# R7FA6M4AF register map
Vendor: Renesas Electronics Corporation; Series: RA6; File version: 1.20.04
CPU: CM33 r0p4, little endian, MPU, FPU, VTOR, 4 interrupt priority bits, 96 interrupts
Registers are 8-bit, read-write, reset 0x0 unless marked. A register's access mark holds for its fields unless they carry their own. Offsets are from the block's base; [hi:lo] are bit positions; {n}, {i} and the like mark numbered series; 'fields as' and 'values as' point back to an identical list; <NAME> marks a mode.

## GPT320 (part 2 of 2) — General PWM 32-bit Timer 0
Base 0x40169000
Same registers: GPT321 0x40169100, GPT322 0x40169200, GPT323 0x40169300
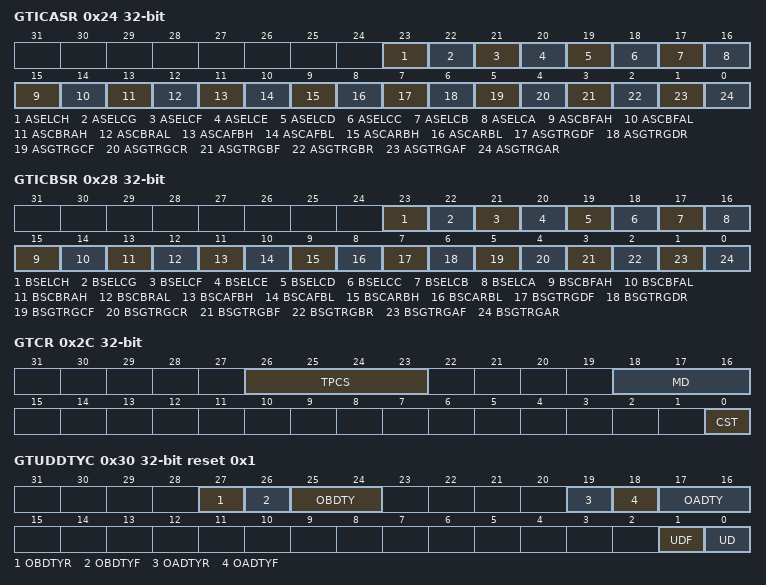
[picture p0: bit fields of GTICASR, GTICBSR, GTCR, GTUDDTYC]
0x24 GTICASR 32-bit — General PWM Timer Input Capture Source Select Register A
  [23] ASELCH — ELC_GPTH Event Source GTCCRA Input Capture Enable
    0=GTCCRA input capture disabled at the ELC_GPTH input; 1=GTCCRA input capture enabled at the ELC_GPTH input
  [22] ASELCG — ELC_GPTG Event Source GTCCRA Input Capture Enable
    0=GTCCRA input capture disabled at the ELC_GPTG input; 1=GTCCRA input capture enabled at the ELC_GPTG input
  [21] ASELCF — ELC_GPTF Event Source GTCCRA Input Capture Enable
    0=GTCCRA input capture disabled at the ELC_GPTF input; 1=GTCCRA input capture enabled at the ELC_GPTF input
  [20] ASELCE — ELC_GPTE Event Source GTCCRA Input Capture Enable
    0=GTCCRA input capture disabled at the ELC_GPTE input; 1=GTCCRA input capture enabled at the ELC_GPTE input
  [19] ASELCD — ELC_GPTD Event Source GTCCRA Input Capture Enable
    0=GTCCRA input capture disabled at the ELC_GPTD input; 1=GTCCRA input capture enabled at the ELC_GPTD input
  [18] ASELCC — ELC_GPTC Event Source GTCCRA Input Capture Enable
    0=GTCCRA input capture disabled at the ELC_GPTC input; 1=GTCCRA input capture enabled at the ELC_GPTC input
  [17] ASELCB — ELC_GPTB Event Source GTCCRA Input Capture Enable
    0=GTCCRA input capture disabled at the ELC_GPTB input; 1=GTCCRA input capture enabled at the ELC_GPTB input
  [16] ASELCA — ELC_GPTA Event Source GTCCRA Input Capture Enable
    0=GTCCRA input capture disabled at the ELC_GPTA input; 1=GTCCRA input capture enabled at the ELC_GPTA input
  [15] ASCBFAH — GTIOCnB Pin Falling Input during GTIOCnA Value High Source GTCCRA Input Capture Enable
    0=GTCCRA input capture disabled on the falling edge of GTIOCnB input when GTIOCnA input is 1; 1=GTCCRA input capture enabled on the falling edge of GTIOCnB input when GTIOCnA input is 1
  [14] ASCBFAL — GTIOCnB Pin Falling Input during GTIOCnA Value Low Source GTCCRA Input Capture Enable
    0=GTCCRA input capture disabled on the falling edge of GTIOCnB input when GTIOCnA input is 0; 1=GTCCRA input capture enabled on the falling edge of GTIOCnB input when GTIOCnA input is 0
  [13] ASCBRAH — GTIOCnB Pin Rising Input during GTIOCnA Value High Source GTCCRA Input Capture Enable
    0=GTCCRA input capture disabled on the rising edge of GTIOCnB input when GTIOCnA input is 1; 1=GTCCRA input capture enabled on the rising edge of GTIOCnB input when GTIOCnA input is 1
  [12] ASCBRAL — GTIOCnB Pin Rising Input during GTIOCnA Value Low Source GTCCRA Input Capture Enable
    0=GTCCRA input capture disabled on the rising edge of GTIOCnB input when GTIOCnA input is 0; 1=GTCCRA input capture enabled on the rising edge of GTIOCnB input when GTIOCnA input is 0
  [11] ASCAFBH — GTIOCnA Pin Falling Input during GTIOCnB Value High Source GTCCRA Input Capture Enable
    0=GTCCRA input capture disabled on the falling edge of GTIOCnA input when GTIOCnB input is 1; 1=GTCCRA input capture enabled on the falling edge of GTIOCnA input when GTIOCnB input is 1
  [10] ASCAFBL — GTIOCnA Pin Falling Input during GTIOCnB Value Low Source GTCCRA Input Capture Enable
    0=GTCCRA input capture disabled on the falling edge of GTIOCnA input when GTIOCnB input is 0; 1=GTCCRA input capture enabled on the falling edge of GTIOCnA input when GTIOCnB input is 0
  [9] ASCARBH — GTIOCnA Pin Rising Input during GTIOCnB Value High Source GTCCRA Input Capture Enable
    0=GTCCRA input capture disabled on the rising edge of GTIOCnA input when GTIOCnB input is 1; 1=GTCCRA input capture enabled on the rising edge of GTIOCnA input when GTIOCnB input is 1
  [8] ASCARBL — GTIOCnA Pin Rising Input during GTIOCnB Value Low Source GTCCRA Input Capture Enable
    0=GTCCRA input capture disabled on the rising edge of GTIOCnA input when GTIOCnB input is 0; 1=GTCCRA input capture enabled on the rising edge of GTIOCnA input when GTIOCnB input is 0
  [7] ASGTRGDF — GTETRGD Pin Falling Input Source GTCCRA Input Capture Enable
    0=GTCCRA input capture disabled on the falling edge of GTETRGD input; 1=GTCCRA input capture enabled on the falling edge of GTETRGD input
  [6] ASGTRGDR — GTETRGD Pin Rising Input Source GTCCRA Input Capture Enable
    0=GTCCRA input capture disabled on the rising edge of GTETRGD input; 1=GTCCRA input capture enabled on the rising edge of GTETRGD input
  [5] ASGTRGCF — GTETRGC Pin Falling Input Source GTCCRA Input Capture Enable
    0=GTCCRA input capture disabled on the falling edge of GTETRGC input; 1=GTCCRA input capture enabled on the falling edge of GTETRGC input
  [4] ASGTRGCR — GTETRGC Pin Rising Input Source GTCCRA Input Capture Enable
    0=GTCCRA input capture disabled on the rising edge of GTETRGC input; 1=GTCCRA input capture enabled on the rising edge of GTETRGC input
  [3] ASGTRGBF — GTETRGB Pin Falling Input Source GTCCRA Input Capture Enable
    0=GTCCRA input capture disabled on the falling edge of GTETRGB input; 1=GTCCRA input capture enabled on the falling edge of GTETRGB input
  [2] ASGTRGBR — GTETRGB Pin Rising Input Source GTCCRA Input Capture Enable
    0=GTCCRA input capture disabled on the rising edge of GTETRGB input; 1=GTCCRA input capture enabled on the rising edge of GTETRGB input
  [1] ASGTRGAF — GTETRGA Pin Falling Input Source GTCCRA Input Capture Enable
    0=GTCCRA input capture disabled on the falling edge of GTETRGA input; 1=GTCCRA input capture enabled on the falling edge of GTETRGA input
  [0] ASGTRGAR — GTETRGA Pin Rising Input Source GTCCRA Input Capture Enable
    0=GTCCRA input capture disabled on the rising edge of GTETRGA input; 1=GTCCRA input capture enabled on the rising edge of GTETRGA input
0x28 GTICBSR 32-bit — General PWM Timer Input Capture Source Select Register B
  [23] BSELCH — ELC_GPTH Event Source GTCCRB Input Capture Enable
    0=GTCCRB input capture disabled at the ELC_GPTH input; 1=GTCCRB input capture enabled at the ELC_GPTH input
  [22] BSELCG — ELC_GPTG Event Source GTCCRB Input Capture Enable
    0=GTCCRB input capture disabled at the ELC_GPTG input; 1=GTCCRB input capture enabled at the ELC_GPTG input
  [21] BSELCF — ELC_GPTF Event Source GTCCRB Input Capture Enable
    0=GTCCRB input capture disabled at the ELC_GPTF input; 1=GTCCRB input capture enabled at the ELC_GPTF input
  [20] BSELCE — ELC_GPTE Event Source GTCCRB Input Capture Enable
    0=GTCCRB input capture disabled at the ELC_GPTE input; 1=GTCCRB input capture enabled at the ELC_GPTE input
  [19] BSELCD — ELC_GPTD Event Source GTCCRB Input Capture Enable
    0=GTCCRB input capture disabled at the ELC_GPTD input; 1=GTCCRB input capture enabled at the ELC_GPTD input
  [18] BSELCC — ELC_GPTC Event Source GTCCRB Input Capture Enable
    0=GTCCRB input capture disabled at the ELC_GPTC input; 1=GTCCRB input capture enabled at the ELC_GPTC input
  [17] BSELCB — ELC_GPTB Event Source GTCCRB Input Capture Enable
    0=GTCCRB input capture disabled at the ELC_GPTB input; 1=GTCCRB input capture enabled at the ELC_GPTB input
  [16] BSELCA — ELC_GPTA Event Source GTCCRB Input Capture Enable
    0=GTCCRB input capture disabled at the ELC_GPTA input; 1=GTCCRB input capture enabled at the ELC_GPTA input
  [15] BSCBFAH — GTIOCnB Pin Falling Input during GTIOCnA Value High Source GTCCRB Input Capture Enable
    0=GTCCRB input capture disabled on the falling edge of GTIOCnB input when GTIOCnA input is 1; 1=GTCCRB input capture enabled on the falling edge of GTIOCnB input when GTIOCnA input is 1
  [14] BSCBFAL — GTIOCnB Pin Falling Input during GTIOCnA Value Low Source GTCCRB Input Capture Enable
    0=GTCCRB input capture disabled on the falling edge of GTIOCnB input when GTIOCnA input is 0; 1=GTCCRB input capture enabled on the falling edge of GTIOCnB input when GTIOCnA input is 0
  [13] BSCBRAH — GTIOCnB Pin Rising Input during GTIOCnA Value High Source GTCCRB Input Capture Enable
    0=GTCCRB input capture disabled on the rising edge of GTIOCnB input when GTIOCnA input is 1; 1=GTCCRB input capture enabled on the rising edge of GTIOCnB input when GTIOCnA input is 1
  [12] BSCBRAL — GTIOCnB Pin Rising Input during GTIOCnA Value Low Source GTCCRB Input Capture Enable
    0=GTCCRB input capture disabled on the rising edge of GTIOCnB input when GTIOCnA input is 0; 1=GTCCRB input capture enabled on the rising edge of GTIOCnB input when GTIOCnA input is 0
  [11] BSCAFBH — GTIOCnA Pin Falling Input during GTIOCnB Value High Source GTCCRB Input Capture Enable
    0=GTCCRB input capture disabled on the falling edge of GTIOCnA input when GTIOCnB input is 1; 1=GTCCRB input capture enabled on the falling edge of GTIOCnA input when GTIOCnB input is 1
  [10] BSCAFBL — GTIOCnA Pin Falling Input during GTIOCnB Value Low Source GTCCRB Input Capture Enable
    0=GTCCRB input capture disabled on the falling edge of GTIOCnA input when GTIOCnB input is 0; 1=GTCCRB input capture enabled on the falling edge of GTIOCnA input when GTIOCnB input is 0
  [9] BSCARBH — GTIOCnA Pin Rising Input during GTIOCnB Value High Source GTCCRB Input Capture Enable
    0=GTCCRB input capture disabled on the rising edge of GTIOCnA input when GTIOCnB input is 1; 1=GTCCRB input capture enabled on the rising edge of GTIOCnA input when GTIOCnB input is 1
  [8] BSCARBL — GTIOCnA Pin Rising Input during GTIOCnB Value Low Source GTCCRB Input Capture Enable
    0=GTCCRB input capture disabled on the rising edge of GTIOCnA input when GTIOCnB input is 0; 1=GTCCRB input capture enabled on the rising edge of GTIOCnA input when GTIOCnB input is 0
  [7] BSGTRGDF — GTETRGD Pin Falling Input Source GTCCRB Input Capture Enable
    0=GTCCRB input capture disabled on the falling edge of GTETRGD input; 1=GTCCRB input capture enabled on the falling edge of GTETRGD input
  [6] BSGTRGDR — GTETRGD Pin Rising Input Source GTCCRB Input Capture Enable
    0=GTCCRB input capture disabled on the rising edge of GTETRGD input; 1=GTCCRB input capture enabled on the rising edge of GTETRGD input
  [5] BSGTRGCF — GTETRGC Pin Falling Input Source GTCCRB Input Capture Enable
    0=GTCCRB input capture disabled on the falling edge of GTETRGC input; 1=GTCCRB input capture enabled on the falling edge of GTETRGC input
  [4] BSGTRGCR — GTETRGC Pin Rising Input Source GTCCRB Input Capture Enable
    0=GTCCRB input capture disabled on the rising edge of GTETRGC input; 1=GTCCRB input capture enabled on the rising edge of GTETRGC input
  [3] BSGTRGBF — GTETRGB Pin Falling Input Source GTCCRB Input Capture Enable
    0=GTCCRB input capture disabled on the falling edge of GTETRGB input; 1=GTCCRB input capture enabled on the falling edge of GTETRGB input
  [2] BSGTRGBR — GTETRGB Pin Rising Input Source GTCCRB Input Capture Enable
    0=GTCCRB input capture disabled on the rising edge of GTETRGB input; 1=GTCCRB input capture enabled on the rising edge of GTETRGB input
  [1] BSGTRGAF — GTETRGA Pin Falling Input Source GTCCRB Input Capture Enable
    0=GTCCRB input capture disabled on the falling edge of GTETRGA input; 1=GTCCRB input capture enabled on the falling edge of GTETRGA input
  [0] BSGTRGAR — GTETRGA Pin Rising Input Source GTCCRB Input Capture Enable
    0=GTCCRB input capture disabled on the rising edge of GTETRGA input; 1=GTCCRB input capture enabled on the rising edge of GTETRGA input
0x2C GTCR 32-bit — General PWM Timer Control Register
  [26:23] TPCS — Timer Prescaler Select
    0=PCLKD/1; 1=PCLKD/2; 2=PCLKD/4; 3=PCLKD/8; 4=PCLKD/16; 5=PCLKD/32; 6=PCLKD/64; 7=Setting prohibited; 8=PCLKD/256; 9=Setting prohibited; 10=PCLKD/1024; 11=Setting prohibited; 12=GTETRGA (Via the POEG); 13=GTETRGB (Via the POEG); 14=GTETRGC (Via the POEG); 15=GTETRGD (Via the POEG)
  [18:16] MD — Mode Select
    0=Saw-wave PWM mode (single buffer or double buffer possible); 1=Saw-wave one-shot pulse mode (fixed buffer operation); 2=Setting prohibited; 3=Setting prohibited; 4=Triangle-wave PWM mode 1 (32-bit transfer at trough) (single buffer or double buffer is possible); 5=Triangle-wave PWM mode 2 (32-bit transfer at crest and trough) (single buffer or double buffer is possible); 6=Triangle-wave PWM mode 3 (64-bit transfer at trough) (fixed buffer operation); 7=Setting prohibited
  [0] CST — Count Start
    0=Count operation is stopped; 1=Count operation is performed
0x30 GTUDDTYC 32-bit reset 0x1 — General PWM Timer Count Direction and Duty Setting Register
  [27] OBDTYR — GTIOCnB Output Value Selecting after Releasing 0%/100% Duty Setting
    0=The function selected by the GTIOB[3:2] bits is applied to the output value when the duty cycle is set after release from the 0 or 100% duty-cycle setting; 1=The function selected by the GTIOB[3:2] bits is applied to the compare match output value which is masked after release from the 0 or 100% duty-cycle setting
  [26] OBDTYF — Forcible GTIOCnB Output Duty Setting
    0=Not forcibly set; 1=Forcibly set
  [25:24] OBDTY — GTIOCnB Output Duty Setting
    0=GTIOCnB pin duty depends on the compare match; 1=GTIOCnB pin duty depends on the compare match; 2=GTIOCnB pin duty 0%; 3=GTIOCnB pin duty 100%
  [19] OADTYR — GTIOCnA Output Value Selecting after Releasing 0%/100% Duty Setting
    0=The function selected by the GTIOA[3:2] bits is applied to the output value when the duty cycle is set after release from the 0 or 100% duty-cycle setting; 1=The function selected by the GTIOA[3:2] bits is applied to the compare match output value which is masked after release from the 0 or 100% duty-cycle setting
  [18] OADTYF — Forcible GTIOCnA Output Duty Setting
    0=Not forcibly set; 1=Forcibly set
  [17:16] OADTY — GTIOCnA Output Duty Setting
    0=GTIOCnA pin duty depends on the compare match; 1=GTIOCnA pin duty depends on the compare match; 2=GTIOCnA pin duty 0%; 3=GTIOCnA pin duty 100%
  [1] UDF — Forcible Count Direction Setting
    0=Not forcibly set; 1=Forcibly set
  [0] UD — Count Direction Setting
    0=GTCNT counts down; 1=GTCNT counts up
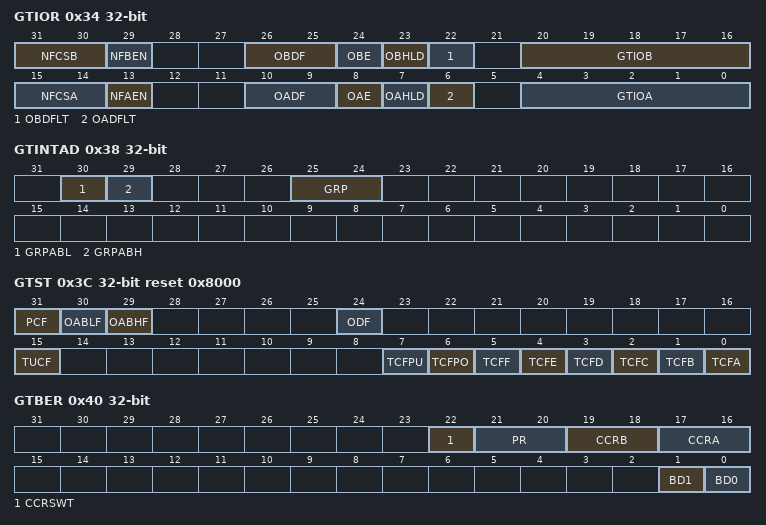
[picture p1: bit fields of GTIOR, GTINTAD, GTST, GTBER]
0x34 GTIOR 32-bit — General PWM Timer I/O Control Register
  [31:30] NFCSB — Noise Filter B Sampling Clock Select
    0=PCLKD/1; 1=PCLKD/4; 2=PCLKD/16; 3=PCLKD/64
  [29] NFBEN — Noise Filter B Enable
    0=The noise filter for the GTIOCnB pin is disabled; 1=The noise filter for the GTIOCnB pin is enabled
  [26:25] OBDF — GTIOCnB Pin Disable Value Setting
    0=None of the below options are specified; 1=GTIOCnB pin is set to Hi-Z in response to controlling the output negation; 2=GTIOCnB pin is set to 0 in response to controlling the output negation; 3=GTIOCnB pin is set to 1 in response to controlling the output negation
  [24] OBE — GTIOCnB Pin Output Enable
    0=Output is disabled; 1=Output is enabled
  [23] OBHLD — GTIOCnB Pin Output Setting at the Start/Stop Count
    0=The GTIOCnB pin output level at the start/stop of counting depends on the register setting; 1=The GTIOCnB pin output level is retained at the start/stop of counting
  [22] OBDFLT — GTIOCnB Pin Output Value Setting at the Count Stop
    0=The GTIOCnB pin outputs low when counting stops; 1=The GTIOCnB pin outputs high when counting stops
  [20:16] GTIOB — GTIOCnB Pin Function Select
  [15:14] NFCSA — Noise Filter A Sampling Clock Select
    0=PCLKD/1; 1=PCLKD/4; 2=PCLKD/16; 3=PCLKD/64
  [13] NFAEN — Noise Filter A Enable
    0=The noise filter for the GTIOCnA pin is disabled; 1=The noise filter for the GTIOCnA pin is enabled
  [10:9] OADF — GTIOCnA Pin Disable Value Setting
    0=None of the below options are specified; 1=GTIOCnA pin is set to Hi-Z in response to controlling the output negation; 2=GTIOCnA pin is set to 0 in response to controlling the output negation; 3=GTIOCnA pin is set to 1 in response to controlling the output negation
  [8] OAE — GTIOCnA Pin Output Enable
    0=Output is disabled; 1=Output is enabled
  [7] OAHLD — GTIOCnA Pin Output Setting at the Start/Stop Count
    0=The GTIOCnA pin output level at the start or stop of counting depends on the register setting; 1=The GTIOCnA pin output level is retained at the start or stop of counting
  [6] OADFLT — GTIOCnA Pin Output Value Setting at the Count Stop
    0=The GTIOCnA pin outputs low when counting stops; 1=The GTIOCnA pin outputs high when counting stops
  [4:0] GTIOA — GTIOCnA Pin Function Select
0x38 GTINTAD 32-bit — General PWM Timer Interrupt Output Setting Register
  [30] GRPABL — Same Time Output Level Low Disable Request Enable
    0=Same time output level low disable request disabled; 1=Same time output level low disable request enabled
  [29] GRPABH — Same Time Output Level High Disable Request Enable
    0=Same time output level high disable request disabled; 1=Same time output level high disable request enabled
  [25:24] GRP — Output Disable Source Select
    0=Group A output disable request is selected; 1=Group B output disable request is selected; 2=Group C output disable request is selected; 3=Group D output disable request is selected
0x3C GTST 32-bit reset 0x8000 — General PWM Timer Status Register
  [31] PCF — Period Count Function Finish Flag
    0=No period count function finish has occurred; 1=A period count function finish has occurred
  [30] OABLF ro — Same Time Output Level Low Flag
    0=No simultaneous generation of 0 both for the GTIOCA and GTIOCB pins has occurred; 1=A simultaneous generation of 0 both for the GTIOCA and GTIOCB pins has occurred
  [29] OABHF ro — Same Time Output Level High Flag
    0=No simultaneous generation of 1 both for the GTIOCA and GTIOCB pins has occurred; 1=A simultaneous generation of 1 both for the GTIOCA and GTIOCB pins has occurred
  [24] ODF ro — Output Disable Flag
    0=No output disable request is generated; 1=An output disable request is generated
  [15] TUCF ro — Count Direction Flag
    0=GTCNT counter counts downward; 1=GTCNT counter counts upward
  [7] TCFPU — Underflow Flag
    0=No underflow (trough) occurred; 1=An underflow (trough) occurred
  [6] TCFPO — Overflow Flag
    0=No overflow (crest) occurred; 1=An overflow (crest) occurred
  [5] TCFF — Input Compare Match Flag F
    0=No compare match of GTCCRF is generated; 1=A compare match of GTCCRF is generated
  [4] TCFE — Input Compare Match Flag E
    0=No compare match of GTCCRE is generated; 1=A compare match of GTCCRE is generated
  [3] TCFD — Input Compare Match Flag D
    0=No compare match of GTCCRD is generated; 1=A compare match of GTCCRD is generated
  [2] TCFC — Input Compare Match Flag C
    0=No compare match of GTCCRC is generated; 1=A compare match of GTCCRC is generated
  [1] TCFB — Input Capture/Compare Match Flag B
    0=No input capture/compare match of GTCCRB is generated; 1=An input capture/compare match of GTCCRB is generated
  [0] TCFA — Input Capture/Compare Match Flag A
    0=No input capture/compare match of GTCCRA is generated; 1=An input capture/compare match of GTCCRA is generated
0x40 GTBER 32-bit — General PWM Timer Buffer Enable Register
  [22] CCRSWT wo — GTCCRA and GTCCRB Forcible Buffer Operation
  [21:20] PR — GTPR Buffer Operation
    0=No buffer operation; 1=Single buffer operation (GTPBR --> GTPR); other=Others (Setting prohibited)
  [19:18] CCRB — GTCCRB Buffer Operation
    0=No buffer operation; 1=Single buffer operation (GTCCRB <----> GTCCRE); other=Others (Double buffer operation (GTCCRB <----> GTCCRE <----> GTCCRF))
  [17:16] CCRA — GTCCRA Buffer Operation
    0=No buffer operation; 1=Single buffer operation (GTCCRA <---->GTCCRC); other=Others (Double buffer operation (GTCCRA <----> GTCCRC <----> GTCCRD))
  [1] BD1 — GTPR Buffer Operation Disable
    0=Buffer operation is enabled; 1=Buffer operation is disabled
  [0] BD0 — GTCCR Buffer Operation Disable
    values as BD1
0x48 GTCNT 32-bit — General PWM Timer Counter
0x4C GTCCRA 32-bit reset 0xFFFFFFFF — General PWM Timer Compare Capture Register A
0x50 GTCCRB 32-bit reset 0xFFFFFFFF — General PWM Timer Compare Capture Register B
0x54 GTCCRC 32-bit reset 0xFFFFFFFF — General PWM Timer Compare Capture Register C
0x58 GTCCRE 32-bit reset 0xFFFFFFFF — General PWM Timer Compare Capture Register E
0x5C GTCCRD 32-bit reset 0xFFFFFFFF — General PWM Timer Compare Capture Register D
0x60 GTCCRF 32-bit reset 0xFFFFFFFF — General PWM Timer Compare Capture Register F
0x64 GTPR 32-bit reset 0xFFFFFFFF — General PWM Timer Cycle Setting Register
0x68 GTPBR 32-bit reset 0xFFFFFFFF — General PWM Timer Cycle Setting Buffer Register
0x88 GTDTCR 32-bit — General PWM Timer Dead Time Control Register
  [0] TDE — Negative-Phase Waveform Setting
    0=GTCCRB is set without using GTDVU; 1=GTDVU is used to set the compare match value for negative-phase waveform with dead time automatically in GTCCRB
0x8C GTDVU 32-bit reset 0xFFFFFFFF — General PWM Timer Dead Time Value Register U
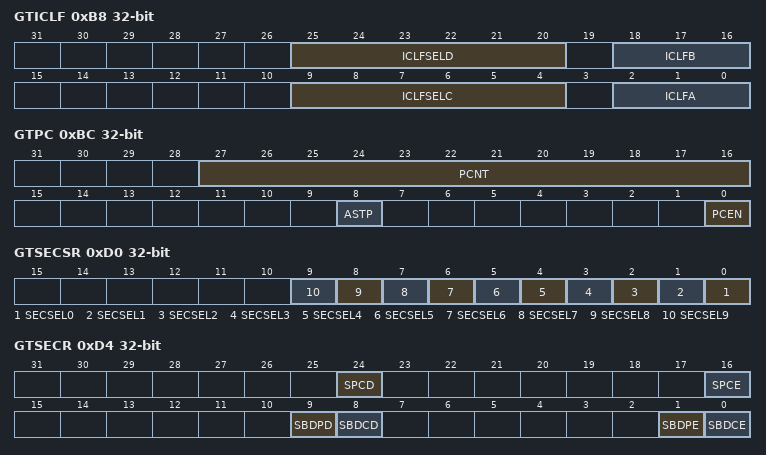
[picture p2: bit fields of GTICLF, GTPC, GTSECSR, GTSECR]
0xB8 GTICLF 32-bit — General PWM Timer Inter Channel Logical Operation Function Setting Register
  [25:20] ICLFSELD — Inter Channel Signal D Select
    0=GTIOC0A; 1=GTIOC0B; 2=GTIOC1A; 3=GTIOC1B; 4=GTIOC2A; 5=GTIOC2B; 6=GTIOC3A; 7=GTIOC3B; 8=GTIOC4A; 9=GTIOC4B; 10=GTIOC5A; 11=GTIOC5B; 12=GTIOC6A; 13=GTIOC6B; 14=GTIOC7A; 15=GTIOC7B; 16=GTIOC8A; 17=GTIOC8B; 18=GTIOC9A; 19=GTIOC9B; other=Others (Setting prohibited)
  [18:16] ICLFB — GTIOCnB Output Logical Operation Function Select
    0=B (no delay); 1=NOT B (no delay); 2=D (1PCLKD delay); 3=NOT D (1PCLKD delay); 4=B AND D (1PCLKD delay); 5=B OR D (1PCLKDn delay); 6=B EXOR D (1PCLKD delay); 7=B NOR D (1PCLKD delay)
  [9:4] ICLFSELC — Inter Channel Signal C Select
    values as ICLFSELD
  [2:0] ICLFA — GTIOCnA Output Logical Operation Function Select
    0=A (no delay); 1=NOT A (no delay); 2=C (1PCLKD delay); 3=NOT C (1PCLKD delay); 4=A AND C (1PCLKD delay); 5=A OR C (1PCLKD delay); 6=A EXOR C (1PCLKD delay); 7=A NOR C (1PCLKD delay)
0xBC GTPC 32-bit — General PWM Timer Period Count Register
  [27:16] PCNT — Period Counter
  [8] ASTP — Automatic Stop Function Enable
    0=Automatic stop function is disabled; 1=Automatic stop function is enabled
  [0] PCEN — Period Count Function Enable
    0=Period count function is disabled; 1=Period count function is enabled
0xD0 GTSECSR 32-bit — General PWM Timer Operation Enable Bit Simultaneous Control Channel Select Register
  [all] fields
    0=Disable simultaneous control; 1=Enable simultaneous control
  [n] SECSEL{n} (n=0..9) — Channel {n} Operation Enable Bit Simultaneous Control Channel Select
0xD4 GTSECR 32-bit — General PWM Timer Operation Enable Bit Simultaneous Control Register
  [24] SPCD — Period Count Function Simultaneous Disable
    0=Disable simultaneous disabling period count function; 1=Disable period count function simultaneously
  [16] SPCE — Period Count Function Simultaneous Enable
    0=Disable simultaneous enabling period count function; 1=Enable period count function simultaneously
  [9] SBDPD — GTPR Register Buffer Operation Simultaneous Disable
    0=Disable simultaneous disabling GTPR buffer operations; 1=Disable GTPR register buffer operations simultaneously
  [8] SBDCD — GTCCR Register Buffer Operation Simultaneous Disable
    0=Disable simultaneous disabling GTCCR buffer operations; 1=Disable GTCCR register buffer operations simultaneously
  [1] SBDPE — GTPR Register Buffer Operation Simultaneous Enable
    0=Disable simultaneous enabling GTPR buffer operations; 1=Enable GTPR register buffer operations simultaneously
  [0] SBDCE — GTCCR Register Buffer Operation Simultaneous Enable
    0=Disable simultaneous enabling GTCCR buffer operations; 1=Enable GTCCR register buffer operations simultaneously

## GPT164 (part 2 of 2) — General PWM 16-bit Timer 4
Base 0x40169400
Same registers: GPT165 0x40169500, GPT166 0x40169600, GPT167 0x40169700, GPT168 0x40169800, GPT169 0x40169900
Registers as GPT320; these are added or differ:
0x4C GTCCRA 32-bit reset 0xFFFF — General PWM Timer Compare Capture Register A
0x50 GTCCRB 32-bit reset 0xFFFF — General PWM Timer Compare Capture Register B
0x54 GTCCRC 32-bit reset 0xFFFF — General PWM Timer Compare Capture Register C
0x58 GTCCRE 32-bit reset 0xFFFF — General PWM Timer Compare Capture Register E
0x5C GTCCRD 32-bit reset 0xFFFF — General PWM Timer Compare Capture Register D
0x60 GTCCRF 32-bit reset 0xFFFF — General PWM Timer Compare Capture Register F
0x64 GTPR 32-bit reset 0xFFFF — General PWM Timer Cycle Setting Register
0x68 GTPBR 32-bit reset 0xFFFF — General PWM Timer Cycle Setting Buffer Register
0x8C GTDVU 32-bit reset 0xFFFF — General PWM Timer Dead Time Value Register U
